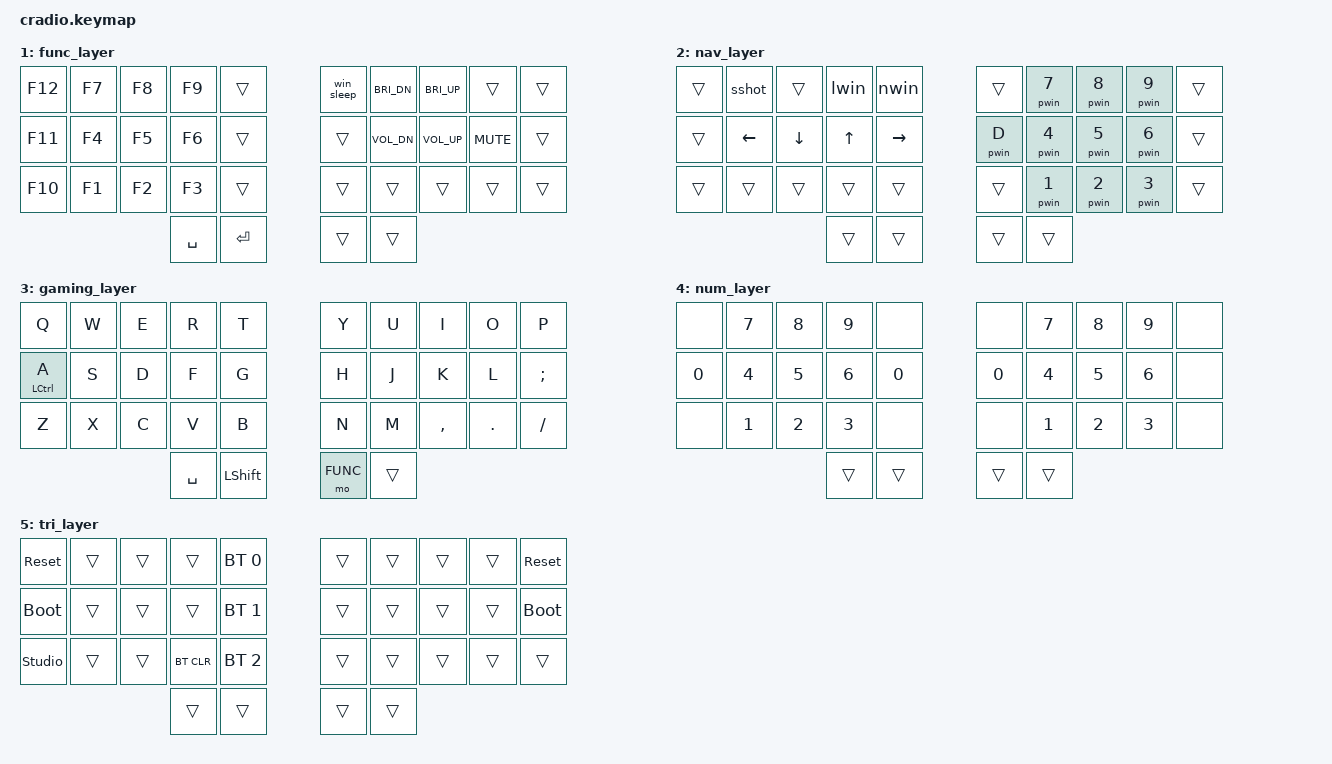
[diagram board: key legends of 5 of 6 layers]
// Copyright (c) 2022 The ZMK Contributors
// SPDX-License-Identifier: MIT

#include <behaviors.dtsi>
#include <dt-bindings/zmk/keys.h>
#include <dt-bindings/zmk/bt.h>

// Home row mods macro
#define HRML(k1,k2,k3,k4) &htl LGUI k1  &htl LALT k2  &htl LSHIFT k3  &htl LCTRL k4
#define HRMR(k1,k2,k3,k4) &htr RCTRL k1  &htr RSHIFT k2  &htr RALT k3  &htr RGUI k4

#define KEYS_L 0 1 2 3 4 10 11 12 13 14 20 21 22 23 24
#define KEYS_R 5 6 7 8 9 15 16 17 18 19 25 26 27 28 29
#define THUMBS 30 31 32 33

#define TRI 5
#define NUMBER 4
#define GAME 3
#define NAV 2
#define FUNC 1
#define DEFAULT 0

#include "combos.dtsi"

/ {
    behaviors {
        htl: hold_tap_left {
            compatible = "zmk,behavior-hold-tap";
            flavor = "balanced";
            tapping-term-ms = <280>;
            quick-tap-ms = <175>;
            require-prior-idle-ms = <150>;
            bindings = <&kp>, <&kp>;
            #binding-cells = <2>;
            hold-trigger-key-positions = <KEYS_R THUMBS>;
            hold-trigger-on-release;
        };
        htr: hold_tap_right {
            compatible = "zmk,behavior-hold-tap";
            flavor = "balanced";
            tapping-term-ms = <280>;
            quick-tap-ms = <175>;
            require-prior-idle-ms = <150>;
            bindings = <&kp>, <&kp>;
            #binding-cells = <2>;
            hold-trigger-key-positions = <KEYS_L THUMBS>;
            hold-trigger-on-release;
        };
        triple_shift: triple_shift_morph {
            compatible = "zmk,behavior-mod-morph";
            bindings = <&sk LSHIFT>, <&caps_word>;
            mods = <(MOD_LSFT)>;
            #binding-cells = <0>;
        };
        lpar_lt: lpar_lthan_morph {
            compatible = "zmk,behavior-mod-morph";
            #binding-cells = <0>;
            bindings = <&kp LPAR>, <&kp LT>;
            mods = <(MOD_LSFT|MOD_RSFT)>;
        };
        rpar_gt: rpar_gthan_morph {
            compatible = "zmk,behavior-mod-morph";
            #binding-cells = <0>;
            bindings = <&kp RPAR>, <&kp GT>;
            mods = <(MOD_LSFT|MOD_RSFT)>;
        };
        comma_semi: comma_semi_morph {
            compatible = "zmk,behavior-mod-morph";
            #binding-cells = <0>;
            bindings = <&kp COMMA>, <&kp SEMI>;
            mods = <(MOD_LSFT|MOD_RSFT)>;
        };
        dot_colon: dot_colon_morph {
            compatible = "zmk,behavior-mod-morph";
            #binding-cells = <0>;
            bindings = <&kp DOT>, <&kp COLON>;
            mods = <(MOD_LSFT|MOD_RSFT)>;
        };
        excl_qmark: excl_qmark_morph {
            compatible = "zmk,behavior-mod-morph";
            #binding-cells = <0>;
            bindings = <&kp EXCL>, <&kp QMARK>;
            mods = <(MOD_LSFT|MOD_RSFT)>;
        };
    };
    conditional_layers {
        compatible = "zmk,conditional-layers";
        tri_layer {
            if-layers = <FUNC NUMBER>;
            then-layer = <TRI>;
        };
    };
    macros {
        nwin: next_window {
            compatible = "zmk,behavior-macro";
            #binding-cells = <0>;
            bindings
                = <&macro_press &kp LALT>
                , <&macro_tap &kp TAB>
                , <&macro_release &kp LALT>
                ;
        };
        lwin: last_window {
            compatible = "zmk,behavior-macro";
            #binding-cells = <0>;
            bindings
                = <&macro_press &kp LALT &kp LSHIFT>
                , <&macro_tap &kp TAB>
                , <&macro_release &kp LALT &kp LSHIFT>
                ;
        };
        pwin: pick_window {
            compatible = "zmk,behavior-macro-one-param";
            wait-ms = <0>;
            tap-ms = <0>;
            #binding-cells = <1>;
            bindings
                = <&macro_press &kp LGUI>
                , <&macro_param_1to1>
                , <&macro_tap &kp MACRO_PLACEHOLDER>
                , <&macro_release &kp LGUI>
                ;
        };
        sshot: screenshot {
            compatible = "zmk,behavior-macro";
            #binding-cells = <0>;
            bindings 
                = <&macro_press &kp LWIN &kp LSHIFT &kp S>
                , <&macro_release &kp LWIN &kp LSHIFT &kp S>
                ;
        };
        win_sleep: win_sleep {
            wait-ms = <50>;
            tap-ms = <5>;
            compatible = "zmk,behavior-macro";
            #binding-cells = <0>;
            bindings = <&kp LG(X) &kp U &kp S>;
        };
    };
    keymap {
        compatible = "zmk,keymap";
        default_layer {
            bindings = <
            //╭──────────┬──────────┬──────────┬──────────┬──────────╮   ╭──────────┬──────────┬──────────┬──────────┬──────────╮
            //│  Q       │  W       │  F       │  P       │  G       │   │  J       │  L       │  U       │  Y       │  ' "     │
                &kp Q      &kp W      &kp F      &kp P      &kp G          &kp J      &kp L      &kp U      &kp Y      &kp SQT
            //├──────────┼──────────┼──────────┼──────────┼──────────┤   ├──────────┼──────────┼──────────┼──────────┼──────────┤
            //│  A       │  R       │  S       │  T       │  D       │   │  H       │  N       │  E       │  I       │  O       │
               HRML(A,         R,         S,         T)     &kp D          &kp H     HRMR(N,         E,         I,         O)
            //├──────────┼──────────┼──────────┼──────────┼──────────┤   ├──────────┼──────────┼──────────┼──────────┼──────────┤
            //│  Z       │  X       │  C       │  V       │  B       │   │  K       │  M       │  , ;     │  . :     │  ! ?     │
                &kp Z      &kp X      &kp C      &kp V      &kp B          &kp K      &kp M     &comma_semi &dot_colon &excl_qmark
            //╰──────────┴──────────┴──────────┼──────────┼──────────┤   ├──────────┼──────────┼──────────┴──────────┴──────────╯
            //                                 │          │          │   │          │          │
                                           &lt NAV SPACE &lt NUMBER ENTER  &mo FUNC   &triple_shift
            //                                 ╰──────────┴──────────╯   ╰──────────┴──────────╯
            >;
        };
        func_layer {
            bindings = <
            //╭──────────┬──────────┬──────────┬──────────┬──────────╮   ╭──────────┬──────────┬──────────┬──────────┬──────────╮
            //│ F12      │ F7       │ F8       │ F9       │          │   │          │          │          │          │          │
                &kp F12    &kp F7     &kp F8     &kp F9     &trans         &win_sleep &kp C_BRI_DN &kp C_BRI_UP  &trans     &trans  
            //├──────────┼──────────┼──────────┼──────────┼──────────┤   ├──────────┼──────────┼──────────┼──────────┼──────────┤
            //│ F11      │ F4       │ F5       │ F6       │          │   │          │          │          │          │          │
                &kp F11    &kp F4     &kp F5     &kp F6     &trans         &trans     &kp C_VOL_DN &kp C_VOL_UP  &kp C_MUTE &trans     
            //├──────────┼──────────┼──────────┼──────────┼──────────┤   ├──────────┼──────────┼──────────┼──────────┼──────────┤
            //│ F10      │ F1       │ F2       │ F3       │          │   │          │          │          │          │          │
                &kp F10    &kp F1     &kp F2     &kp F3     &trans         &trans     &trans     &trans     &trans     &trans
            //╰──────────┴──────────┴──────────┼──────────┼──────────┤   ├──────────┼──────────┼──────────┴──────────┴──────────╯
            //                                 │          │          │   │          │          │
                                                 &kp SPACE  &kp ENTER      &trans     &trans
            //                                 ╰──────────┴──────────╯   ╰──────────┴──────────╯
            >;
        };
        nav_layer {
            bindings = <
            //╭──────────┬──────────┬──────────┬──────────┬──────────╮   ╭──────────┬──────────┬──────────┬──────────┬──────────╮
            //│          │  SSHOT   │          │  LWIN    │  NWIN    │   │          │          │          │          │          │
                &trans     &sshot     &trans     &lwin      &nwin          &trans     &pwin N7   &pwin N8   &pwin N9   &trans 
            //├──────────┼──────────┼──────────┼──────────┼──────────┤   ├──────────┼──────────┼──────────┼──────────┼──────────┤
            //│          │          │          │          │          │   │          │          │          │          │          │
                &trans     &kp LEFT   &kp DOWN   &kp UP     &kp RIGHT      &pwin D    &pwin N4   &pwin N5   &pwin N6   &trans
            //├──────────┼──────────┼──────────┼──────────┼──────────┤   ├──────────┼──────────┼──────────┼──────────┼──────────┤
            //│          │          │          │          │          │   │          │          │          │          │          │
                &trans     &trans     &trans     &trans     &trans         &trans     &pwin N1   &pwin N2   &pwin N3   &trans
            //╰──────────┴──────────┴──────────┼──────────┼──────────┤   ├──────────┼──────────┼──────────┴──────────┴──────────╯
            //                                 │          │          │   │          │          │
                                                 &trans     &trans         &trans     &trans
            //                                 ╰──────────┴──────────╯   ╰──────────┴──────────╯
            >;
        };
        gaming_layer {
            bindings = <
            //╭──────────┬──────────┬──────────┬──────────┬──────────╮   ╭──────────┬──────────┬──────────┬──────────┬──────────╮
            //│          │          │          │          │          │   │          │          │          │          │          │
                &kp Q      &kp W      &kp E      &kp R      &kp T          &kp Y      &kp U      &kp I      &kp O      &kp P
            //├──────────┼──────────┼──────────┼──────────┼──────────┤   ├──────────┼──────────┼──────────┼──────────┼──────────┤
            //│          │          │          │          │          │   │          │          │          │          │          │
             &htl LCTRL A  &kp S      &kp D      &kp F      &kp G          &kp H      &kp J      &kp K      &kp L      &kp SEMI          
            //├──────────┼──────────┼──────────┼──────────┼──────────┤   ├──────────┼──────────┼──────────┼──────────┼──────────┤
            //│          │          │          │          │          │   │          │          │          │          │          │
                &kp Z      &kp X      &kp C      &kp V      &kp B          &kp N      &kp M      &kp COMMA  &kp DOT    &kp FSLH
            //╰──────────┴──────────┴──────────┼──────────┼──────────┤   ├──────────┼──────────┼──────────┴──────────┴──────────╯
            //                                 │          │          │   │          │          │
                                                 &kp SPACE  &kp LSHIFT     &mo FUNC   &trans
            //                                 ╰──────────┴──────────╯   ╰──────────┴──────────╯
            >;
        };
        num_layer {
            bindings = <
            //╭──────────┬──────────┬──────────┬──────────┬──────────╮   ╭──────────┬──────────┬──────────┬──────────┬──────────╮
            //│          │          │          │          │          │   │          │  7       │  8       │  9       │          │
                &none      &kp N7     &kp N8     &kp N9     &none          &none      &kp N7     &kp N8     &kp N9     &none  
            //├──────────┼──────────┼──────────┼──────────┼──────────┤   ├──────────┼──────────┼──────────┼──────────┼──────────┤
            //│          │          │          │          │          │   │  0       │  4       │  5       │  6       │          │
                &kp N0     &kp N4     &kp N5     &kp N6     &kp N0         &kp N0     &kp N4     &kp N5     &kp N6     &none    
            //├──────────┼──────────┼──────────┼──────────┼──────────┤   ├──────────┼──────────┼──────────┼──────────┼──────────┤
            //│          │          │          │          │          │   │          │  1       │  2       │  3       │          │
                &none      &kp N1     &kp N2     &kp N3     &none          &none      &kp N1     &kp N2     &kp N3     &none
            //╰──────────┴──────────┴──────────┼──────────┼──────────┤   ├──────────┼──────────┼──────────┴──────────┴──────────╯
            //                                 │          │          │   │          │          │
                                                 &trans     &trans         &trans     &trans
            //                                 ╰──────────┴──────────╯   ╰──────────┴──────────╯
            >;
        };
        tri_layer {
            bindings = <
            //╭──────────┬──────────┬──────────┬──────────┬──────────╮   ╭──────────┬──────────┬──────────┬──────────┬──────────╮
            //│ RESET    │          │          │          │PROFILE 0 │   │          │          │          │          │  RESET   │
               &sys_reset  &trans     &trans     &trans     &bt BT_SEL 0   &trans     &trans     &trans     &trans     &sys_reset
            //├──────────┼──────────┼──────────┼──────────┼──────────┤   ├──────────┼──────────┼──────────┼──────────┼──────────┤
            //│BOOTLOADER│          │          │          │PROFILE 1 │   │          │          │          │          │BOOTLOADER│
              &bootloader  &trans     &trans     &trans     &bt BT_SEL 1   &trans     &trans     &trans     &trans     &bootloader
            //├──────────┼──────────┼──────────┼──────────┼──────────┤   ├──────────┼──────────┼──────────┼──────────┼──────────┤
            //│ZMK STUDIO│          │          │ CLEAR BT │PROFILE 2 │   │          │          │          │          │          │
            &studio_unlock &trans     &trans     &bt BT_CLR &bt BT_SEL 2   &trans     &trans     &trans     &trans     &trans
            //╰──────────┴──────────┴──────────┼──────────┼──────────┤   ├──────────┼──────────┼──────────┴──────────┴──────────╯
            //                                 │          │          │   │          │          │
                                                 &trans     &trans         &trans     &trans
            //                                 ╰──────────┴──────────╯   ╰──────────┴──────────╯
            >;
        };
    };
};
